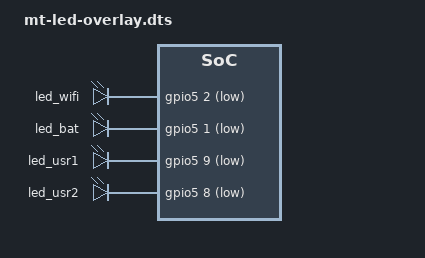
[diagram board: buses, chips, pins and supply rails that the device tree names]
/*
 * Copyright (C) 2019 - All Rights Reserved by 
 * filename : imx-fire-led-overlay.dts
 * brief : Device Tree overlay for EBF6ull led device
 * author : embedfire
 * date : 2019-11-15 
 * version : A001
 */
 /dts-v1/;
 /plugin/;
#include "../imx6ul-pinfunc.h"
#include "dt-bindings/gpio/gpio.h"
 / {
        fragment@0 {
            target-path = "/";
            __overlay__ {
                normal_led{
                    compatible = "gpio-leds";
                    led_wifi {
                        pinctrl-names = "default";
                        pinctrl-0 = <&pinctrl_led_wifi>;
                        label = "led_wifi";
                        gpios = <&gpio5 2 GPIO_ACTIVE_LOW>;
                        default-state = "off";
                        linux,default-trigger = "none";                       
                    };

                    led_bat {
                        pinctrl-names = "default";
                        pinctrl-0 = <&pinctrl_led_bat>;    
                        label = "led_bat";
                        gpios = <&gpio5 1 GPIO_ACTIVE_LOW>;
                        default-state = "off";
                        linux,default-trigger = "none";                           
                    };

                    led_usr1 {
                        pinctrl-names = "default";
                        pinctrl-0 = <&pinctrl_led_usr1>;    
                        label = "led_usr1";
                        gpios = <&gpio5 9 GPIO_ACTIVE_LOW>;
                        default-state = "off";
                        linux,default-trigger = "none";                           
                    };

                    led_usr2 {
                        pinctrl-names = "default";
                        pinctrl-0 = <&pinctrl_led_usr2>;    
                        label = "led_usr2";
                        gpios = <&gpio5 8 GPIO_ACTIVE_LOW>;
                        default-state = "off";
                        linux,default-trigger = "none";                           
                    };
                };
            };
        };

        fragment@1 {
            target= <&iomuxc>;
            __overlay__{
                pinctrl_led_wifi:ledwifigrp{
                    fsl,pins = < MX6UL_PAD_SNVS_TAMPER2__GPIO5_IO02 0x1b0b0 >;
                };

                pinctrl_led_bat:ledbatgrp{
                    fsl,pins = < MX6UL_PAD_SNVS_TAMPER1__GPIO5_IO01 0x1b0b0 >;
                };

                pinctrl_led_usr1:ledusr1grp{
                    fsl,pins = < MX6UL_PAD_SNVS_TAMPER9__GPIO5_IO09 0x1b0b0 >;
                };

                pinctrl_led_usr2:ledusr2grp{
                    fsl,pins = < MX6UL_PAD_SNVS_TAMPER8__GPIO5_IO08 0x1b0b0 >;
                };
            };
	};
 };
